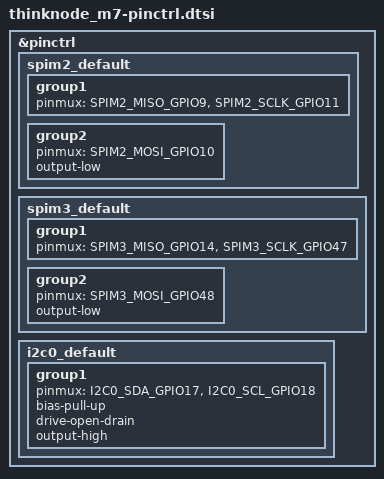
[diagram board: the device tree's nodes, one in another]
/*
 * SPDX-License-Identifier: MIT
 * Elecrow ThinkNode M7 — Pin Control Definitions
 *
 * Pin mapping, agreed by the Arduino MeshCore variants/thinknode_m7, the
 * Meshtastic ELECROW-ThinkNode-M7 variant, and an independent ESPHome port:
 *   SPI2:     SCLK=GPIO11, MOSI=GPIO10, MISO=GPIO9   (LR1110 NSS=GPIO12)
 *   SPI3:     SCLK=GPIO47, MOSI=GPIO48, MISO=GPIO14  (CH390 CS=GPIO21)
 *   I2C0:     SDA=GPIO17, SCL=GPIO18                 (no device fitted)
 *   Console:  uart0 GPIO43/44 via esp32s3_console_uart0.dtsi
 */

#include <zephyr/dt-bindings/pinctrl/esp-pinctrl-common.h>
#include <zephyr/dt-bindings/pinctrl/esp32s3-pinctrl.h>
#include <zephyr/dt-bindings/pinctrl/esp32s3-gpio-sigmap.h>

&pinctrl {
	/* SPI2 — LR1110 radio (CS via cs-gpios) */
	spim2_default: spim2_default {
		group1 {
			pinmux = <SPIM2_MISO_GPIO9>,
				 <SPIM2_SCLK_GPIO11>;
		};
		group2 {
			pinmux = <SPIM2_MOSI_GPIO10>;
			output-low;
		};
	};

	/* SPI3 — CH390 Ethernet (CS via cs-gpios). These pads have no SPI3
	 * IOMUX route, so every signal goes through the GPIO matrix. */
	spim3_default: spim3_default {
		group1 {
			pinmux = <SPIM3_MISO_GPIO14>,
				 <SPIM3_SCLK_GPIO47>;
		};
		group2 {
			pinmux = <SPIM3_MOSI_GPIO48>;
			output-low;
		};
	};

	/* I2C0 — no device fitted on the tested unit; the RTC socket is
	 * probed by autodiscovery. */
	i2c0_default: i2c0_default {
		group1 {
			pinmux = <I2C0_SDA_GPIO17>,
				 <I2C0_SCL_GPIO18>;
			bias-pull-up;
			drive-open-drain;
			output-high;
		};
	};
};
